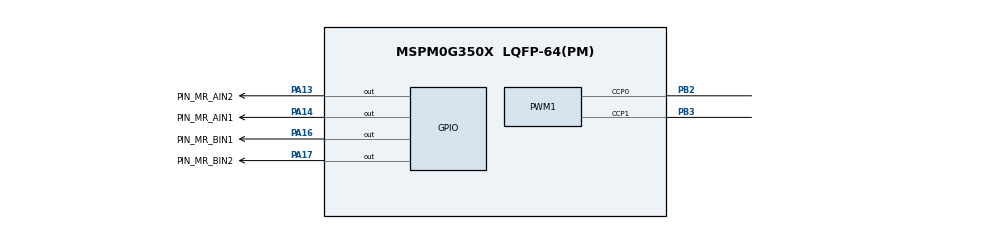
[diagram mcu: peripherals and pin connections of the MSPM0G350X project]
/**
 * @cliArgs --device "MSPM0G350X" --part "Default" --package "LQFP-64(PM)" --product "mspm0_sdk@2.05.01.00"
 * @versions {"tool":"1.24.0+4110"}
 */

/**
 * Import the modules used in this configuration.
 */
const GPIO   = scripting.addModule("/ti/driverlib/GPIO", {}, false);
const GPIO1  = GPIO.addInstance();
const PWM    = scripting.addModule("/ti/driverlib/PWM", {}, false);
const PWM1   = PWM.addInstance();
const SYSCTL = scripting.addModule("/ti/driverlib/SYSCTL");

/**
 * Write custom configuration values to the imported modules.
 */
GPIO1.$name                         = "GPIO_Motor";
GPIO1.associatedPins.create(4);
GPIO1.associatedPins[0].$name       = "PIN_MR_AIN1";
GPIO1.associatedPins[0].pin.$assign = "PA14";
GPIO1.associatedPins[1].$name       = "PIN_MR_AIN2";
GPIO1.associatedPins[1].pin.$assign = "PA13";
GPIO1.associatedPins[2].$name       = "PIN_MR_BIN1";
GPIO1.associatedPins[2].pin.$assign = "PA16";
GPIO1.associatedPins[3].$name       = "PIN_MR_BIN2";
GPIO1.associatedPins[3].pin.$assign = "PA17";

const Board = scripting.addModule("/ti/driverlib/Board", {}, false);

PWM1.$name                      = "PWM_0";
PWM1.timerCount                 = 32000;
PWM1.peripheral.ccp0Pin.$assign = "PB2";
PWM1.peripheral.ccp1Pin.$assign = "PB3";
PWM1.PWM_CHANNEL_0.$name        = "ti_driverlib_pwm_PWMTimerCC0";
PWM1.PWM_CHANNEL_0.dutyCycle    = 75;
PWM1.PWM_CHANNEL_1.$name        = "ti_driverlib_pwm_PWMTimerCC1";
PWM1.PWM_CHANNEL_1.dutyCycle    = 50;
PWM1.ccp0PinConfig.$name        = "ti_driverlib_gpio_GPIOPinGeneric0";
PWM1.ccp1PinConfig.$name        = "ti_driverlib_gpio_GPIOPinGeneric1";

SYSCTL.forceDefaultClkConfig = true;
SYSCTL.clockTreeEn           = true;

/**
 * Pinmux solution for unlocked pins/peripherals. This ensures that minor changes to the automatic solver in a future
 * version of the tool will not impact the pinmux you originally saw.  These lines can be completely deleted in order to
 * re-solve from scratch.
 */
Board.peripheral.$suggestSolution          = "DEBUGSS";
Board.peripheral.swclkPin.$suggestSolution = "PA20";
Board.peripheral.swdioPin.$suggestSolution = "PA19";
PWM1.peripheral.$suggestSolution           = "TIMA1";
